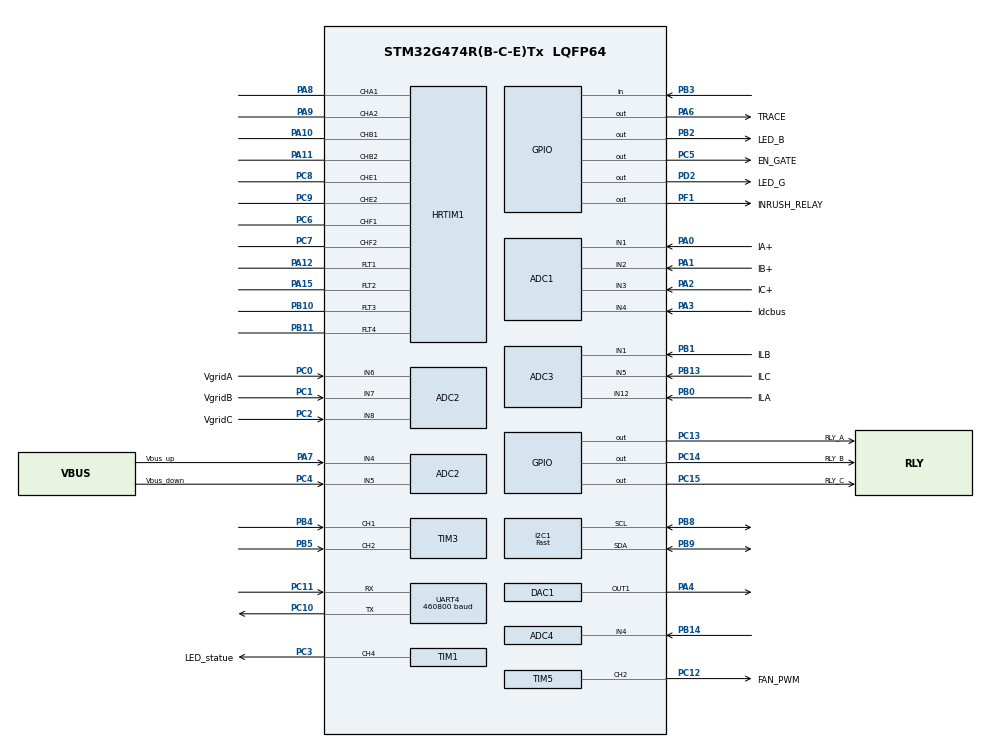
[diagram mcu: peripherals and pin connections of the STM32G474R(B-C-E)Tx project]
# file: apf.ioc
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ADC1.Channel-6\#ChannelRegularConversion=ADC_CHANNEL_4
ADC1.ContinuousConvMode=ENABLE
ADC1.DMAContinuousRequests=ENABLE
ADC1.EOCSelection=ADC_EOC_SEQ_CONV
ADC1.EnableInjectedConversion=ENABLE
ADC1.EnableInjectedOversampling=DISABLE
ADC1.EnableRegularConversion=ENABLE
ADC1.ExternalTrigConv=ADC_EXTERNALTRIG_HRTIM_TRG3
ADC1.ExternalTrigInjecConv=ADC_EXTERNALTRIGINJEC_HRTIM_TRG2
ADC1.InjNumberOfConversion=3
ADC1.InjectedChannel-1\#ChannelInjectedConversion=ADC_CHANNEL_1
ADC1.InjectedChannel-2\#ChannelInjectedConversion=ADC_CHANNEL_2
ADC1.InjectedChannel-3\#ChannelInjectedConversion=ADC_CHANNEL_3
ADC1.InjectedOffsetNumber-1\#ChannelInjectedConversion=ADC_OFFSET_NONE
ADC1.InjectedOffsetNumber-2\#ChannelInjectedConversion=ADC_OFFSET_NONE
ADC1.InjectedOffsetNumber-3\#ChannelInjectedConversion=ADC_OFFSET_NONE
ADC1.InjectedRank-1\#ChannelInjectedConversion=1
ADC1.InjectedRank-2\#ChannelInjectedConversion=2
ADC1.InjectedRank-3\#ChannelInjectedConversion=3
ADC1.InjectedSamplingTime-1\#ChannelInjectedConversion=ADC_SAMPLETIME_6CYCLES_5
ADC1.InjectedSamplingTime-2\#ChannelInjectedConversion=ADC_SAMPLETIME_6CYCLES_5
ADC1.InjectedSamplingTime-3\#ChannelInjectedConversion=ADC_SAMPLETIME_6CYCLES_5
ADC1.NbrOfConversionFlag=1
ADC1.OffsetNumber-6\#ChannelRegularConversion=ADC_OFFSET_NONE
ADC1.OversamplingMode=ENABLE
ADC1.Rank-6\#ChannelRegularConversion=1
ADC1.Rank1_Channel=ADC_CHANNEL_1
ADC1.Rank2_Channel=ADC_CHANNEL_2
ADC1.Rank3_Channel=ADC_CHANNEL_3
ADC1.Rank4_Channel=ADC_CHANNEL_4
ADC1.Ratio=ADC_OVERSAMPLING_RATIO_4
ADC1.RightBitShift=ADC_RIGHTBITSHIFT_2
ADC1.SamplingTime-6\#ChannelRegularConversion=ADC_SAMPLETIME_12CYCLES_5
ADC1.master=1
ADC2.Channel-1\#ChannelRegularConversion=ADC_CHANNEL_4
ADC2.Channel-2\#ChannelRegularConversion=ADC_CHANNEL_5
ADC2.ContinuousConvMode=ENABLE
ADC2.DMAContinuousRequests=ENABLE
ADC2.EOCSelection=ADC_EOC_SEQ_CONV
ADC2.EnableInjectedConversion=ENABLE
ADC2.ExternalTrigConv=ADC_EXTERNALTRIG_HRTIM_TRG3
ADC2.ExternalTrigInjecConv=ADC_EXTERNALTRIGINJEC_HRTIM_TRG2
ADC2.InjNumberOfConversion=3
ADC2.InjectedChannel-3\#ChannelInjectedConversion=ADC_CHANNEL_6
ADC2.InjectedChannel-4\#ChannelInjectedConversion=ADC_CHANNEL_7
ADC2.InjectedChannel-5\#ChannelInjectedConversion=ADC_CHANNEL_8
ADC2.InjectedOffsetNumber-3\#ChannelInjectedConversion=ADC_OFFSET_NONE
ADC2.InjectedOffsetNumber-4\#ChannelInjectedConversion=ADC_OFFSET_NONE
ADC2.InjectedOffsetNumber-5\#ChannelInjectedConversion=ADC_OFFSET_NONE
ADC2.InjectedRank-3\#ChannelInjectedConversion=1
ADC2.InjectedRank-4\#ChannelInjectedConversion=2
ADC2.InjectedRank-5\#ChannelInjectedConversion=3
ADC2.InjectedSamplingTime-3\#ChannelInjectedConversion=ADC_SAMPLETIME_6CYCLES_5
ADC2.InjectedSamplingTime-4\#ChannelInjectedConversion=ADC_SAMPLETIME_6CYCLES_5
ADC2.InjectedSamplingTime-5\#ChannelInjectedConversion=ADC_SAMPLETIME_6CYCLES_5
ADC2.NbrOfConversion=2
ADC2.NbrOfConversionFlag=1
ADC2.OffsetNumber-1\#ChannelRegularConversion=ADC_OFFSET_NONE
ADC2.OffsetNumber-2\#ChannelRegularConversion=ADC_OFFSET_NONE
ADC2.OversamplingMode=ENABLE
ADC2.Rank-1\#ChannelRegularConversion=1
ADC2.Rank-2\#ChannelRegularConversion=2
ADC2.Rank1_Channel=ADC_CHANNEL_6
ADC2.Rank2_Channel=ADC_CHANNEL_7
ADC2.Rank3_Channel=ADC_CHANNEL_8
ADC2.Ratio=ADC_OVERSAMPLING_RATIO_4
ADC2.RightBitShift=ADC_RIGHTBITSHIFT_2
ADC2.SamplingTime-1\#ChannelRegularConversion=ADC_SAMPLETIME_12CYCLES_5
ADC2.SamplingTime-2\#ChannelRegularConversion=ADC_SAMPLETIME_12CYCLES_5
ADC3.EnableInjectedConversion=ENABLE
ADC3.EnableRegularConversion=DISABLE
ADC3.ExternalTrigInjecConv=ADC_EXTERNALTRIGINJEC_HRTIM_TRG3
ADC3.InjNumberOfConversion=3
ADC3.InjectedChannel-2\#ChannelInjectedConversion=ADC_CHANNEL_12
ADC3.InjectedChannel-3\#ChannelInjectedConversion=ADC_CHANNEL_1
ADC3.InjectedChannel-4\#ChannelInjectedConversion=ADC_CHANNEL_5
ADC3.InjectedOffsetNumber-2\#ChannelInjectedConversion=ADC_OFFSET_NONE
ADC3.InjectedOffsetNumber-3\#ChannelInjectedConversion=ADC_OFFSET_NONE
ADC3.InjectedOffsetNumber-4\#ChannelInjectedConversion=ADC_OFFSET_NONE
ADC3.InjectedRank-2\#ChannelInjectedConversion=1
ADC3.InjectedRank-3\#ChannelInjectedConversion=2
ADC3.InjectedRank-4\#ChannelInjectedConversion=3
ADC3.InjectedSamplingTime-2\#ChannelInjectedConversion=ADC_SAMPLETIME_12CYCLES_5
ADC3.InjectedSamplingTime-3\#ChannelInjectedConversion=ADC_SAMPLETIME_12CYCLES_5
ADC3.InjectedSamplingTime-4\#ChannelInjectedConversion=ADC_SAMPLETIME_12CYCLES_5
ADC3.Overrun=ADC_OVR_DATA_OVERWRITTEN
ADC3.Rank1_Channel=ADC_CHANNEL_12
ADC3.Rank2_Channel=ADC_CHANNEL_1
ADC3.Rank3_Channel=ADC_CHANNEL_5
ADC3.master=1
ADC4.EnableInjectedConversion=ENABLE
ADC4.EnableInjectedOversampling=ENABLE
ADC4.EnableRegularConversion=DISABLE
ADC4.InjNumberOfConversion=2
ADC4.InjOversamplingRatio=ADC_OVERSAMPLING_RATIO_16
ADC4.InjOversamplingRightShift=ADC_RIGHTBITSHIFT_4
ADC4.InjectedChannel-6\#ChannelInjectedConversion=ADC_CHANNEL_4
ADC4.InjectedChannel-7\#ChannelInjectedConversion=ADC_CHANNEL_VREFINT
ADC4.InjectedConvMode=None
ADC4.InjectedOffsetNumber-6\#ChannelInjectedConversion=ADC_OFFSET_NONE
ADC4.InjectedOffsetNumber-7\#ChannelInjectedConversion=ADC_OFFSET_NONE
ADC4.InjectedRank-6\#ChannelInjectedConversion=1
ADC4.InjectedRank-7\#ChannelInjectedConversion=2
ADC4.InjectedSamplingTime-6\#ChannelInjectedConversion=ADC_SAMPLETIME_640CYCLES_5
ADC4.InjectedSamplingTime-7\#ChannelInjectedConversion=ADC_SAMPLETIME_640CYCLES_5
ADC4.Rank1_Channel=ADC_CHANNEL_4
ADC4.injectedQueueMode=DISABLE
Dma.ADC1.1.Direction=DMA_PERIPH_TO_MEMORY
Dma.ADC1.1.EventEnable=DISABLE
Dma.ADC1.1.Instance=DMA1_Channel1
Dma.ADC1.1.MemDataAlignment=DMA_MDATAALIGN_WORD
Dma.ADC1.1.MemInc=DMA_MINC_ENABLE
Dma.ADC1.1.Mode=DMA_CIRCULAR
Dma.ADC1.1.PeriphDataAlignment=DMA_PDATAALIGN_HALFWORD
Dma.ADC1.1.PeriphInc=DMA_PINC_DISABLE
Dma.ADC1.1.Polarity=HAL_DMAMUX_REQ_GEN_RISING
Dma.ADC1.1.Priority=DMA_PRIORITY_LOW
Dma.ADC1.1.RequestNumber=1
Dma.ADC1.1.SignalID=NONE
Dma.ADC1.1.SyncEnable=DISABLE
Dma.ADC1.1.SyncPolarity=HAL_DMAMUX_SYNC_NO_EVENT
Dma.ADC1.1.SyncRequestNumber=1
Dma.ADC1.1.SyncSignalID=NONE
Dma.ADC2.2.Direction=DMA_PERIPH_TO_MEMORY
Dma.ADC2.2.EventEnable=DISABLE
Dma.ADC2.2.Instance=DMA1_Channel2
Dma.ADC2.2.MemDataAlignment=DMA_MDATAALIGN_WORD
Dma.ADC2.2.MemInc=DMA_MINC_ENABLE
Dma.ADC2.2.Mode=DMA_CIRCULAR
Dma.ADC2.2.PeriphDataAlignment=DMA_PDATAALIGN_HALFWORD
Dma.ADC2.2.PeriphInc=DMA_PINC_DISABLE
Dma.ADC2.2.Polarity=HAL_DMAMUX_REQ_GEN_RISING
Dma.ADC2.2.Priority=DMA_PRIORITY_LOW
Dma.ADC2.2.RequestNumber=1
Dma.ADC2.2.SignalID=NONE
Dma.ADC2.2.SyncEnable=DISABLE
Dma.ADC2.2.SyncPolarity=HAL_DMAMUX_SYNC_NO_EVENT
Dma.ADC2.2.SyncRequestNumber=1
Dma.ADC2.2.SyncSignalID=NONE
Dma.Request0=UART4_TX
Dma.Request1=ADC1
Dma.Request2=ADC2
Dma.UART4_TX.0.Direction=DMA_MEMORY_TO_PERIPH
Dma.UART4_TX.0.EventEnable=DISABLE
Dma.UART4_TX.0.Instance=DMA2_Channel5
Dma.UART4_TX.0.MemDataAlignment=DMA_MDATAALIGN_BYTE
Dma.UART4_TX.0.MemInc=DMA_MINC_ENABLE
Dma.UART4_TX.0.Mode=DMA_NORMAL
Dma.UART4_TX.0.PeriphDataAlignment=DMA_PDATAALIGN_BYTE
Dma.UART4_TX.0.PeriphInc=DMA_PINC_DISABLE
Dma.UART4_TX.0.Polarity=HAL_DMAMUX_REQ_GEN_RISING
Dma.UART4_TX.0.Priority=DMA_PRIORITY_LOW
Dma.UART4_TX.0.RequestNumber=1
Dma.UART4_TX.0.SignalID=NONE
Dma.UART4_TX.0.SyncEnable=DISABLE
Dma.UART4_TX.0.SyncPolarity=HAL_DMAMUX_SYNC_NO_EVENT
Dma.UART4_TX.0.SyncRequestNumber=1
Dma.UART4_TX.0.SyncSignalID=NONE
HRTIM1.ADCTrigger2_Source1=HRTIM_ADCTRIGGEREVENT24_TIMERB_CMP2
HRTIM1.ADCTrigger3_Source1=HRTIM_ADCTRIGGEREVENT13_TIMERB_PERIOD
HRTIM1.ADCTrigger_Id1=__NULL
HRTIM1.ADCTrigger_Id2=HRTIM_ADCTRIGGER_2
HRTIM1.ADCTrigger_Id3=HRTIM_ADCTRIGGER_3
HRTIM1.CompareUnit1-Output_TA1TA2=HRTIM_COMPAREUNIT_1
HRTIM1.CompareUnit1-Output_TB1TB2=HRTIM_COMPAREUNIT_1
HRTIM1.CompareUnit1-Output_TE1TE2=HRTIM_COMPAREUNIT_1
HRTIM1.CompareUnit1-Output_TF1TF2=HRTIM_COMPAREUNIT_1
HRTIM1.CompareUnit2-Output_TB1TB2=HRTIM_COMPAREUNIT_2
HRTIM1.CompareUnit3-Output_TB1TB2=__NULL
HRTIM1.CompareValue1-Output_TA1TA2=1000
HRTIM1.CounterFaultLine1=0
HRTIM1.CounterFaultLine4=0
HRTIM1.DeadTimeInsertion-Output_TA1TA2=HRTIM_TIMDEADTIMEINSERTION_ENABLED
HRTIM1.DeadTimeInsertion-Output_TB1TB2=HRTIM_TIMDEADTIMEINSERTION_ENABLED
HRTIM1.DeadTimeInsertion-Output_TE1TE2=HRTIM_TIMDEADTIMEINSERTION_ENABLED
HRTIM1.DeadTimeInsertion-Output_TF1TF2=HRTIM_TIMDEADTIMEINSERTION_ENABLED
HRTIM1.Enable_FaultLine1=HRTIM_FAULTMODECTL_DISABLED
HRTIM1.Enable_FaultLine2=HRTIM_FAULTMODECTL_DISABLED
HRTIM1.Enable_FaultLine3=HRTIM_FAULTMODECTL_DISABLED
HRTIM1.Enable_FaultLine4=HRTIM_FAULTMODECTL_DISABLED
HRTIM1.EventEnableA-Output_TA1TA2=__NULL
HRTIM1.FaultEnable_Source1-Output_TA1TA2=HRTIM_TIMFAULTENABLE_FAULT1
HRTIM1.FaultEnable_Source1-Output_TB1TB2=HRTIM_TIMFAULTENABLE_FAULT1
HRTIM1.FaultEnable_Source1-Output_TE1TE2=HRTIM_TIMFAULTENABLE_FAULT1
HRTIM1.FaultEnable_Source1-Output_TF1TF2=HRTIM_TIMFAULTENABLE_FAULT1
HRTIM1.FaultEnable_Source2-Output_TA1TA2=HRTIM_TIMFAULTENABLE_FAULT2
HRTIM1.FaultEnable_Source2-Output_TB1TB2=HRTIM_TIMFAULTENABLE_FAULT2
HRTIM1.FaultEnable_Source2-Output_TE1TE2=HRTIM_TIMFAULTENABLE_FAULT2
HRTIM1.FaultEnable_Source2-Output_TF1TF2=HRTIM_TIMFAULTENABLE_FAULT2
HRTIM1.FaultEnable_Source3-Output_TA1TA2=HRTIM_TIMFAULTENABLE_FAULT3
HRTIM1.FaultEnable_Source3-Output_TB1TB2=HRTIM_TIMFAULTENABLE_FAULT3
HRTIM1.FaultEnable_Source3-Output_TE1TE2=HRTIM_TIMFAULTENABLE_FAULT3
HRTIM1.FaultEnable_Source3-Output_TF1TF2=HRTIM_TIMFAULTENABLE_FAULT3
HRTIM1.FaultEnable_Source4-Output_TA1TA2=HRTIM_TIMFAULTENABLE_FAULT4
HRTIM1.FaultEnable_Source4-Output_TB1TB2=HRTIM_TIMFAULTENABLE_FAULT4
HRTIM1.FaultEnable_Source4-Output_TE1TE2=HRTIM_TIMFAULTENABLE_FAULT4
HRTIM1.FaultEnable_Source4-Output_TF1TF2=HRTIM_TIMFAULTENABLE_FAULT4
HRTIM1.FaultLevel1-Output_TA1TA2=HRTIM_OUTPUTFAULTLEVEL_INACTIVE
HRTIM1.FaultLevel1-Output_TB1TB2=HRTIM_OUTPUTFAULTLEVEL_INACTIVE
HRTIM1.FaultLevel1-Output_TE1TE2=HRTIM_OUTPUTFAULTLEVEL_INACTIVE
HRTIM1.FaultLevel1-Output_TF1TF2=HRTIM_OUTPUTFAULTLEVEL_INACTIVE
HRTIM1.FaultLevel2-Output_TA1TA2=HRTIM_OUTPUTFAULTLEVEL_INACTIVE
HRTIM1.FaultLevel2-Output_TB1TB2=HRTIM_OUTPUTFAULTLEVEL_INACTIVE
HRTIM1.FaultLevel2-Output_TE1TE2=HRTIM_OUTPUTFAULTLEVEL_INACTIVE
HRTIM1.FaultLevel2-Output_TF1TF2=HRTIM_OUTPUTFAULTLEVEL_INACTIVE
HRTIM1.Filter_FaultLine1=HRTIM_FAULTFILTER_13
HRTIM1.Filter_FaultLine2=HRTIM_FAULTFILTER_13
HRTIM1.Filter_FaultLine3=HRTIM_FAULTFILTER_13
HRTIM1.Filter_FaultLine4=HRTIM_FAULTFILTER_13
HRTIM1.GreaterCMP1_TA=HRTIM_TIMERGTCMP1_EQUAL
HRTIM1.NumberADCTriggerSource2=1
HRTIM1.NumberADCTriggerSource3=1
HRTIM1.NumberFaultEnable-Output_TA1TA2=4
HRTIM1.NumberFaultEnable-Output_TB1TB2=4
HRTIM1.NumberFaultEnable-Output_TE1TE2=4
HRTIM1.NumberFaultEnable-Output_TF1TF2=4
HRTIM1.NumberResetSource1-Output_TA1TA2=1
HRTIM1.NumberResetSource1-Output_TB1TB2=1
HRTIM1.NumberResetSource1-Output_TE1TE2=1
HRTIM1.NumberResetSource1-Output_TF1TF2=1
HRTIM1.NumberResetSource2_TB=0
HRTIM1.NumberResetSource2_TE=0
HRTIM1.NumberSetSource1-Output_TA1TA2=1
HRTIM1.NumberSetSource1-Output_TB1TB2=1
HRTIM1.NumberSetSource1-Output_TE1TE2=1
HRTIM1.NumberSetSource1-Output_TF1TF2=1
HRTIM1.NumberSetSource2_TA=0
HRTIM1.NumberUpdateTrigger-Output_TA1TA2=0
HRTIM1.NumberUpdateTrigger-Output_TB1TB2=0
HRTIM1.NumberUpdateTrigger-Output_TE1TE2=0
HRTIM1.NumberUpdateTrigger-Output_TF1TF2=0
HRTIM1.ORingUpdateSource_ADCTrigger2=HRTIM_ADCTRIGGERUPDATE_TIMER_B
HRTIM1.ORingUpdateSource_ADCTrigger3=HRTIM_ADCTRIGGERUPDATE_TIMER_B
HRTIM1.Polarity1-Output_TA1TA2=HRTIM_OUTPUTPOLARITY_HIGH
HRTIM1.Polarity1-Output_TB1TB2=HRTIM_OUTPUTPOLARITY_HIGH
HRTIM1.Polarity1-Output_TE1TE2=HRTIM_OUTPUTPOLARITY_HIGH
HRTIM1.Polarity1-Output_TF1TF2=HRTIM_OUTPUTPOLARITY_HIGH
HRTIM1.Polarity2-Output_TB1TB2=HRTIM_OUTPUTPOLARITY_HIGH
HRTIM1.Polarity2-Output_TE1TE2=HRTIM_OUTPUTPOLARITY_HIGH
HRTIM1.Polarity2-Output_TF1TF2=HRTIM_OUTPUTPOLARITY_HIGH
HRTIM1.Polarity_FaultLine1=HRTIM_FAULTPOLARITY_LOW
HRTIM1.Polarity_FaultLine2=HRTIM_FAULTPOLARITY_LOW
HRTIM1.Polarity_FaultLine3=HRTIM_FAULTPOLARITY_LOW
HRTIM1.Polarity_FaultLine4=HRTIM_FAULTPOLARITY_LOW
HRTIM1.PreloadEnable-Output_TA1TA2=HRTIM_PRELOAD_ENABLED
HRTIM1.PreloadEnable-Output_TB1TB2=HRTIM_PRELOAD_ENABLED
HRTIM1.PreloadEnable-Output_TE1TE2=HRTIM_PRELOAD_ENABLED
HRTIM1.PreloadEnable-Output_TF1TF2=HRTIM_PRELOAD_ENABLED
HRTIM1.PrescalerDead-Output_TA1TA2=HRTIM_TIMDEADTIME_PRESCALERRATIO_DIV1
HRTIM1.PrescalerDead-Output_TB1TB2=HRTIM_TIMDEADTIME_PRESCALERRATIO_DIV1
HRTIM1.PrescalerDead-Output_TE1TE2=HRTIM_TIMDEADTIME_PRESCALERRATIO_DIV1
HRTIM1.PrescalerDead-Output_TF1TF2=HRTIM_TIMDEADTIME_PRESCALERRATIO_DIV1
HRTIM1.PrescalerFault=HRTIM_FAULTPRESCALER_DIV1
HRTIM1.ReSyncUpdate-Output_TB1TB2=HRTIM_TIMERESYNC_UPDATE_UNCONDITIONAL
HRTIM1.ResetModeFaultLine1=HRTIM_FAULTCOUNTERRST_CONDITIONAL
HRTIM1.ResetModeFaultLine2=HRTIM_FAULTCOUNTERRST_CONDITIONAL
HRTIM1.ResetModeFaultLine3=HRTIM_FAULTCOUNTERRST_CONDITIONAL
HRTIM1.ResetModeFaultLine4=HRTIM_FAULTCOUNTERRST_CONDITIONAL
HRTIM1.ResetOutput1_Source1-Output_TA1TA2=HRTIM_OUTPUTRESET_TIMCMP1
HRTIM1.ResetOutput1_Source1-Output_TB1TB2=HRTIM_OUTPUTRESET_TIMCMP1
HRTIM1.ResetOutput1_Source1-Output_TE1TE2=HRTIM_OUTPUTRESET_TIMCMP1
HRTIM1.ResetOutput1_Source1-Output_TF1TF2=HRTIM_OUTPUTRESET_TIMCMP1
HRTIM1.ResetUpdate-Output_TA1TA2=HRTIM_TIMUPDATEONRESET_ENABLED
HRTIM1.ResetUpdate-Output_TB1TB2=HRTIM_TIMUPDATEONRESET_ENABLED
HRTIM1.ResetUpdate-Output_TE1TE2=HRTIM_TIMUPDATEONRESET_ENABLED
HRTIM1.ResetUpdate-Output_TF1TF2=HRTIM_TIMUPDATEONRESET_ENABLED
HRTIM1.SetOutput1_Source1-Output_TA1TA2=HRTIM_OUTPUTSET_TIMCMP1
HRTIM1.SetOutput1_Source1-Output_TB1TB2=HRTIM_OUTPUTSET_TIMCMP1
HRTIM1.SetOutput1_Source1-Output_TE1TE2=HRTIM_OUTPUTSET_TIMCMP1
HRTIM1.SetOutput1_Source1-Output_TF1TF2=HRTIM_OUTPUTSET_TIMCMP1
HRTIM1.SwapA=__NULL
HRTIM1.UpDownMode-Output_TA1TA2=HRTIM_TIMERUPDOWNMODE_UPDOWN
HRTIM1.UpDownMode-Output_TB1TB2=HRTIM_TIMERUPDOWNMODE_UPDOWN
HRTIM1.UpDownMode-Output_TE1TE2=HRTIM_TIMERUPDOWNMODE_UPDOWN
HRTIM1.UpDownMode-Output_TF1TF2=HRTIM_TIMERUPDOWNMODE_UPDOWN
HRTIM1.postscaler2=1
I2C1.I2C_Coeff_DF=2
I2C1.I2C_Speed_Mode=I2C_Fast
I2C1.Timing=0x10802C9A
Mcu.Family=STM32G4
Mcu.Name=STM32G474R(B-C-E)Tx
Mcu.Package=LQFP64
Mcu.UserConstants=FANTIMERARR,(6800)
NVIC.ADC1_2_IRQn=true\:0\:0\:false\:false\:true\:true\:true\:true
NVIC.ADC4_IRQn=true\:0\:0\:false\:false\:true\:true\:true\:true
NVIC.DMA1_Channel1_IRQn=true\:0\:0\:false\:false\:true\:false\:true\:true
NVIC.DMA1_Channel2_IRQn=true\:0\:0\:false\:false\:true\:false\:true\:true
NVIC.DMA2_Channel5_IRQn=true\:0\:0\:false\:false\:true\:false\:true\:true
NVIC.HRTIM1_FLT_IRQn=true\:0\:0\:false\:false\:true\:true\:true\:true
NVIC.PriorityGroup=NVIC_PRIORITYGROUP_4
PA0.GPIO_Label=IA+
PA0.Mode=IN1-Single-Ended
PA0.Signal=ADC1_IN1
PA1.GPIO_Label=IB+
PA1.Mode=IN2-Single-Ended
PA1.Signal=ADC1_IN2
PA10.Mode=Output_TB1TB2
PA10.Signal=HRTIM1_CHB1
PA11.Mode=Output_TB1TB2
PA11.Signal=HRTIM1_CHB2
PA12.GPIO_PuPd=GPIO_PULLUP
PA12.Mode=Fault_Enable1
PA12.Signal=HRTIM1_FLT1
PA13.Mode=Serial_Wire
PA13.Signal=SYS_JTMS-SWDIO
PA14.Mode=Serial_Wire
PA14.Signal=SYS_JTCK-SWCLK
PA15.GPIO_PuPd=GPIO_PULLUP
PA15.Mode=Fault_Enable2
PA15.Signal=HRTIM1_FLT2
PA2.GPIO_Label=IC+
PA2.Mode=IN3-Single-Ended
PA2.Signal=ADC1_IN3
PA3.GPIO_Label=Idcbus
PA3.Mode=IN4-Single-Ended
PA3.Signal=ADC1_IN4
PA4.Signal=COMP_DAC11_group
PA5.Signal=COMP_DAC12_group
PA6.GPIO_Label=TRACE
PA6.GPIO_Speed=GPIO_SPEED_FREQ_HIGH
PA6.Signal=GPIO_Output
PA7.GPIO_Label=Vbus_up
PA7.Mode=IN4-Single-Ended
PA7.Signal=ADC2_IN4
PA8.Mode=Output_TA1TA2
PA8.Signal=HRTIM1_CHA1
PA9.Mode=Output_TA1TA2
PA9.Signal=HRTIM1_CHA2
PB0.GPIO_Label=ILA
PB0.Mode=IN12-Single-Ended
PB0.Signal=ADC3_IN12
PB1.GPIO_Label=ILB
PB1.Mode=IN1-Single-Ended
PB1.Signal=ADC3_IN1
PB10.GPIO_PuPd=GPIO_PULLUP
PB10.Mode=Fault_Enable3
PB10.Signal=HRTIM1_FLT3
PB11.GPIO_PuPd=GPIO_PULLUP
PB11.Mode=Fault_Enable4
PB11.Signal=HRTIM1_FLT4
PB13.GPIO_Label=ILC
PB13.Mode=IN5-Single-Ended
PB13.Signal=ADC3_IN5
PB14.Mode=IN4-Single-Ended
PB14.Signal=ADC4_IN4
PB2.GPIO_Label=LED_B
PB2.Signal=GPIO_Output
PB3.Signal=GPIO_Input
PB4.Signal=S_TIM3_CH1
PB5.Signal=S_TIM3_CH2
PB6.Signal=USART1_TX
PB7.Signal=USART1_RX
PB8-BOOT0.Mode=I2C
PB8-BOOT0.Signal=I2C1_SCL
PB9.Mode=I2C
PB9.Signal=I2C1_SDA
PC0.GPIO_Label=VgridA
PC0.Mode=IN6-Single-Ended
PC0.Signal=ADC2_IN6
PC1.GPIO_Label=VgridB
PC1.Mode=IN7-Single-Ended
PC1.Signal=ADC2_IN7
PC10.Mode=Asynchronous
PC10.Signal=UART4_TX
PC11.Mode=Asynchronous
PC11.Signal=UART4_RX
PC12.GPIO_Label=FAN_PWM
PC12.Signal=S_TIM5_CH2
PC13.GPIO_Label=RLY_A
PC13.Signal=GPIO_Output
PC14-OSC32_IN.GPIO_Label=RLY_B
PC14-OSC32_IN.Signal=GPIO_Output
PC15-OSC32_OUT.GPIO_Label=RLY_C
PC15-OSC32_OUT.Signal=GPIO_Output
PC2.GPIO_Label=VgridC
PC2.Mode=IN8-Single-Ended
PC2.Signal=ADC2_IN8
PC3.GPIO_Label=LED_statue
PC3.Signal=S_TIM1_CH4
PC4.GPIO_Label=Vbus_down
PC4.Mode=IN5-Single-Ended
PC4.Signal=ADC2_IN5
PC5.GPIO_Label=EN_GATE
PC5.PinState=GPIO_PIN_SET
PC5.Signal=GPIO_Output
PC6.Mode=Output_TF1TF2
PC6.Signal=HRTIM1_CHF1
PC7.Mode=Output_TF1TF2
PC7.Signal=HRTIM1_CHF2
PC8.Mode=Output_TE1TE2
PC8.Signal=HRTIM1_CHE1
PC9.Mode=Output_TE1TE2
PC9.Signal=HRTIM1_CHE2
PD2.GPIO_Label=LED_G
PD2.Signal=GPIO_Output
PF0-OSC_IN.Mode=HSE-External-Clock-Source
PF0-OSC_IN.Signal=RCC_OSC_IN
PF1-OSC_OUT.GPIO_Label=INRUSH_RELAY
PF1-OSC_OUT.Signal=GPIO_Output
ProjectManager.HeapSize=0x200
ProjectManager.StackSize=0x400
ProjectManager.TargetToolchain=STM32CubeIDE
RCC.ADC12Freq_Value=170000000
RCC.ADC345Freq_Value=170000000
RCC.AHBFreq_Value=170000000
RCC.APB1Freq_Value=170000000
RCC.APB1TimFreq_Value=170000000
RCC.APB2Freq_Value=170000000
RCC.APB2TimFreq_Value=170000000
RCC.CortexFreq_Value=170000000
RCC.DATA_CACHE_ENABLE=1
RCC.EXTERNAL_CLOCK_VALUE=12288000
RCC.HCLKFreq_Value=170000000
RCC.HSE_VALUE=25000000
RCC.HSI48_VALUE=48000000
RCC.HSI_VALUE=16000000
RCC.INSTRUCTION_CACHE_ENABLE=1
RCC.LSE_VALUE=32768
RCC.PLLM=RCC_PLLM_DIV5
RCC.PLLN=68
RCC.PLLSourceVirtual=RCC_PLLSOURCE_HSE
RCC.PREFETCH_ENABLE=1
RCC.SYSCLKFreq_VALUE=170000000
RCC.SYSCLKSource=RCC_SYSCLKSOURCE_PLLCLK
RCC.USBFreq_Value=170000000
RCC.VCOOutputFreq_Value=340000000
SH.COMP_DAC11_group.0=DAC1_OUT1,DAC_OUT1
SH.COMP_DAC12_group.0=DAC1_OUT2
SH.S_TIM1_CH4.0=TIM1_CH4,PWM Generation4 CH4
SH.S_TIM3_CH1.0=TIM3_CH1,Encoder_Interface
SH.S_TIM3_CH2.0=TIM3_CH2,Encoder_Interface
SH.S_TIM5_CH2.0=TIM5_CH2,PWM Generation2 CH2
SYS.TrimmingMode=__NULL
SYS.VoltageScaling=SYSCFG_VREFBUF_VOLTAGE_SCALE2
TIM1.Channel-PWM\ Generation4\ CH4=TIM_CHANNEL_4
TIM1.Dithering=Disable
TIM5.Channel-PWM\ Generation2\ CH2=TIM_CHANNEL_2
TIM5.PeriodNoDither=FANTIMERARR-1
TIM5.PulseNoDither_2=0
UART4.BaudRate=460800
UART4.DMADisableonRxErrorParam=UART_ADVFEATURE_DMA_DISABLEONRXERROR
UART4.OverrunDisableParam=UART_ADVFEATURE_OVERRUN_DISABLE
VP_ADC4_Vref_Input.Mode=IN-Vrefint
VP_SYS_VS_DBSignals.Mode=DisableDeadBatterySignals
VP_TIM1_VS_ClockSourceINT.Mode=Internal
VP_TIM5_VS_ClockSourceINT.Mode=Internal
VREF+.Mode=InternalMode
VREF+.Signal=VREFBUF_OUT
board=custom

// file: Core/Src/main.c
/* USER CODE BEGIN Header */
/**
  ******************************************************************************
  * @file           : main.c
  * @brief          : Main program body
  ******************************************************************************
  * @attention
  *
  * Copyright (c) 2023 STMicroelectronics.
  * All rights reserved.
  *
  * This software is licensed under terms that can be found in the LICENSE file
  * in the root directory of this software component.
  * If no LICENSE file comes with this software, it is provided AS-IS.
  *
  ******************************************************************************
  */
/* USER CODE END Header */
#include "main.h"
#include "adc.h"
#include "dac.h"
#include "dma.h"
#include "hrtim.h"
#include "i2c.h"
#include "tim.h"
#include "usart.h"
#include "gpio.h"

/* USER CODE BEGIN Includes */
#include "../BoardHAL/BoardHAL.h"
#include "../../Drivers/OLED/oled.h"
/* USER CODE END Includes */

void SystemClock_Config(void);

int main(void)
{

  /* MCU Configuration--------------------------------------------------------*/

  /* Reset of all peripherals, Initializes the Flash interface and the Systick. */
  LL_APB2_GRP1_EnableClock(LL_APB2_GRP1_PERIPH_SYSCFG);
  LL_APB1_GRP1_EnableClock(LL_APB1_GRP1_PERIPH_PWR);

  /* System interrupt init*/
  NVIC_SetPriorityGrouping(NVIC_PRIORITYGROUP_4);

  /* SysTick_IRQn interrupt configuration */
  NVIC_SetPriority(SysTick_IRQn, NVIC_EncodePriority(NVIC_GetPriorityGrouping(),15, 0));

  /** Configure the internal voltage reference buffer voltage scale
  */
  LL_VREFBUF_SetVoltageScaling(LL_VREFBUF_VOLTAGE_SCALE2);

  /** Enable the Internal Voltage Reference buffer
  */
  LL_VREFBUF_Enable();

  /** Configure the internal voltage reference buffer high impedance mode
  */
  LL_VREFBUF_DisableHIZ();

  /** Disable the internal Pull-Up in Dead Battery pins of UCPD peripheral
  */
  LL_PWR_DisableUCPDDeadBattery();

  /* Configure the system clock */
  SystemClock_Config();

  /* Initialize all configured peripherals */
  MX_GPIO_Init();
  MX_DMA_Init();
  MX_ADC1_Init();
  MX_ADC2_Init();
  MX_HRTIM1_Init();
  MX_ADC3_Init();
  MX_ADC4_Init();
  MX_TIM3_Init();
  MX_UART4_Init();
  MX_TIM1_Init();
  MX_TIM5_Init();
  MX_I2C1_Init();
  MX_DAC1_Init();

  /* Infinite loop */
  /* USER CODE BEGIN WHILE */
  PFC_HAL_setupDevice();
  while (1)
  {
    // no reach here
    /* USER CODE END WHILE */

  }
}

void SystemClock_Config(void)
{
  LL_FLASH_SetLatency(LL_FLASH_LATENCY_4);
  while(LL_FLASH_GetLatency() != LL_FLASH_LATENCY_4)
  {
  }
  LL_PWR_EnableRange1BoostMode();
  LL_RCC_HSE_EnableBypass();
  LL_RCC_HSE_Enable();
   /* Wait till HSE is ready */
  while(LL_RCC_HSE_IsReady() != 1)
  {
  }

  LL_RCC_PLL_ConfigDomain_SYS(LL_RCC_PLLSOURCE_HSE, LL_RCC_PLLM_DIV_5, 68, LL_RCC_PLLR_DIV_2);
  LL_RCC_PLL_EnableDomain_SYS();
  LL_RCC_PLL_Enable();
   /* Wait till PLL is ready */
  while(LL_RCC_PLL_IsReady() != 1)
  {
  }

  LL_RCC_SetSysClkSource(LL_RCC_SYS_CLKSOURCE_PLL);
  LL_RCC_SetAHBPrescaler(LL_RCC_SYSCLK_DIV_2);
   /* Wait till System clock is ready */
  while(LL_RCC_GetSysClkSource() != LL_RCC_SYS_CLKSOURCE_STATUS_PLL)
  {
  }

  /* Insure 1us transition state at intermediate medium speed clock*/
  for (__IO uint32_t i = (170 >> 1); i !=0; i--);

  /* Set AHB prescaler*/
  LL_RCC_SetAHBPrescaler(LL_RCC_SYSCLK_DIV_1);
  LL_RCC_SetAPB1Prescaler(LL_RCC_APB1_DIV_1);
  LL_RCC_SetAPB2Prescaler(LL_RCC_APB2_DIV_1);

  LL_Init1msTick(170000000);

  LL_SetSystemCoreClock(170000000);
}

void Error_Handler(void)
{
  __disable_irq();
  while (1)
  {
  }
}
